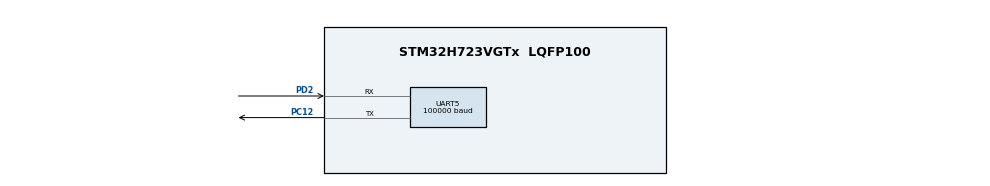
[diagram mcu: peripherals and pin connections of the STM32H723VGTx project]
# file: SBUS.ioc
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CORTEX_M7.default_mode_Activation=0
Dma.Request0=UART5_RX
Dma.UART5_RX.0.Direction=DMA_PERIPH_TO_MEMORY
Dma.UART5_RX.0.EventEnable=DISABLE
Dma.UART5_RX.0.FIFOMode=DMA_FIFOMODE_DISABLE
Dma.UART5_RX.0.Instance=DMA1_Stream0
Dma.UART5_RX.0.MemDataAlignment=DMA_MDATAALIGN_BYTE
Dma.UART5_RX.0.MemInc=DMA_MINC_ENABLE
Dma.UART5_RX.0.Mode=DMA_CIRCULAR
Dma.UART5_RX.0.PeriphDataAlignment=DMA_PDATAALIGN_BYTE
Dma.UART5_RX.0.PeriphInc=DMA_PINC_DISABLE
Dma.UART5_RX.0.Polarity=HAL_DMAMUX_REQ_GEN_RISING
Dma.UART5_RX.0.Priority=DMA_PRIORITY_VERY_HIGH
Dma.UART5_RX.0.RequestNumber=1
Dma.UART5_RX.0.SignalID=NONE
Dma.UART5_RX.0.SyncEnable=DISABLE
Dma.UART5_RX.0.SyncPolarity=HAL_DMAMUX_SYNC_NO_EVENT
Dma.UART5_RX.0.SyncRequestNumber=1
Dma.UART5_RX.0.SyncSignalID=NONE
Mcu.Family=STM32H7
Mcu.Name=STM32H723VGTx
Mcu.Package=LQFP100
NVIC.DMA1_Stream0_IRQn=true\:0\:0\:false\:false\:true\:false\:true\:true
NVIC.PriorityGroup=NVIC_PRIORITYGROUP_4
NVIC.UART5_IRQn=true\:0\:0\:false\:false\:true\:true\:true\:true
PA13(JTMS/SWDIO).Mode=Serial_Wire
PA13(JTMS/SWDIO).Signal=DEBUG_JTMS-SWDIO
PA14(JTCK/SWCLK).Mode=Serial_Wire
PA14(JTCK/SWCLK).Signal=DEBUG_JTCK-SWCLK
PC12.GPIO_Speed=GPIO_SPEED_FREQ_VERY_HIGH
PC12.Mode=Asynchronous
PC12.Signal=UART5_TX
PD2.GPIO_Speed=GPIO_SPEED_FREQ_VERY_HIGH
PD2.Mode=Asynchronous
PD2.Signal=UART5_RX
PH0-OSC_IN.Mode=HSE-External-Oscillator
PH0-OSC_IN.Signal=RCC_OSC_IN
PH1-OSC_OUT.Mode=HSE-External-Oscillator
PH1-OSC_OUT.Signal=RCC_OSC_OUT
ProjectManager.HeapSize=0x200
ProjectManager.StackSize=0x400
ProjectManager.TargetToolchain=MDK-ARM V5.32
RCC.ADCFreq_Value=48375000
RCC.APB1Freq_Value=120000000
RCC.APB2Freq_Value=120000000
RCC.APB3Freq_Value=120000000
RCC.APB4Freq_Value=120000000
RCC.CortexFreq_Value=480000000
RCC.D1PPRE=RCC_APB3_DIV2
RCC.D2PPRE1=RCC_APB1_DIV2
RCC.D2PPRE2=RCC_APB2_DIV2
RCC.D3PPRE=RCC_APB4_DIV2
RCC.DIVM1=2
RCC.DIVN1=40
RCC.DIVP1=1
RCC.HCLKFreq_Value=240000000
RCC.HPRE=RCC_HCLK_DIV2
RCC.HSE_VALUE=24000000
RCC.PLLFRACN=0
RCC.PLLSourceVirtual=RCC_PLLSOURCE_HSE
RCC.SYSCLKFreq_VALUE=480000000
RCC.SYSCLKSource=RCC_SYSCLKSOURCE_PLLCLK
RCC.USBFreq_Value=240000000
UART5.BaudRate=100000
UART5.Parity=PARITY_EVEN
UART5.StopBits=UART_STOPBITS_2
UART5.WordLength=WORDLENGTH_9B
VP_MEMORYMAP_VS_MEMORYMAP.Mode=CurAppReg
board=custom

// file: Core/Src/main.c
/* USER CODE BEGIN Header */
/**
  ******************************************************************************
  * @file           : main.c
  * @brief          : Main program body
  ******************************************************************************
  * @attention
  *
  * Copyright (c) 2025 STMicroelectronics.
  * All rights reserved.
  *
  * This software is licensed under terms that can be found in the LICENSE file
  * in the root directory of this software component.
  * If no LICENSE file comes with this software, it is provided AS-IS.
  *
  ******************************************************************************
  */
/* USER CODE END Header */
#include "main.h"
#include "dma.h"
#include "memorymap.h"
#include "usart.h"
#include "gpio.h"

/* USER CODE BEGIN Includes */
#include "bsp_usart.h"
/* USER CODE END Includes */

void SystemClock_Config(void);

int main(void)
{

  /* MCU Configuration--------------------------------------------------------*/

  /* Reset of all peripherals, Initializes the Flash interface and the Systick. */
  HAL_Init();

  /* Configure the system clock */
  SystemClock_Config();

  /* Initialize all configured peripherals */
  MX_GPIO_Init();
  MX_DMA_Init();
  MX_UART5_Init();
  /* USER CODE BEGIN 2 */

  USART_RxDMA_MultiBuffer_Init(&huart5, (uint32_t *) SBUS_MultiRx_Buf[0], (uint32_t *) SBUS_MultiRx_Buf[1], SBUS_RX_BUF_NUM);

  /* USER CODE END 2 */

  /* Infinite loop */
  while (1)
  {

  }
}

void SystemClock_Config(void)
{
  RCC_OscInitTypeDef RCC_OscInitStruct = {0};
  RCC_ClkInitTypeDef RCC_ClkInitStruct = {0};

  /** Supply configuration update enable
  */
  HAL_PWREx_ConfigSupply(PWR_LDO_SUPPLY);

  /** Configure the main internal regulator output voltage
  */
  __HAL_PWR_VOLTAGESCALING_CONFIG(PWR_REGULATOR_VOLTAGE_SCALE0);

  while(!__HAL_PWR_GET_FLAG(PWR_FLAG_VOSRDY)) {}

  /** Initializes the RCC Oscillators according to the specified parameters
  * in the RCC_OscInitTypeDef structure.
  */
  RCC_OscInitStruct.OscillatorType = RCC_OSCILLATORTYPE_HSE;
  RCC_OscInitStruct.HSEState = RCC_HSE_ON;
  RCC_OscInitStruct.PLL.PLLState = RCC_PLL_ON;
  RCC_OscInitStruct.PLL.PLLSource = RCC_PLLSOURCE_HSE;
  RCC_OscInitStruct.PLL.PLLM = 2;
  RCC_OscInitStruct.PLL.PLLN = 40;
  RCC_OscInitStruct.PLL.PLLP = 1;
  RCC_OscInitStruct.PLL.PLLQ = 2;
  RCC_OscInitStruct.PLL.PLLR = 2;
  RCC_OscInitStruct.PLL.PLLRGE = RCC_PLL1VCIRANGE_3;
  RCC_OscInitStruct.PLL.PLLVCOSEL = RCC_PLL1VCOWIDE;
  RCC_OscInitStruct.PLL.PLLFRACN = 0;
  if (HAL_RCC_OscConfig(&RCC_OscInitStruct) != HAL_OK)
  {
    Error_Handler();
  }

  /** Initializes the CPU, AHB and APB buses clocks
  */
  RCC_ClkInitStruct.ClockType = RCC_CLOCKTYPE_HCLK|RCC_CLOCKTYPE_SYSCLK
                              |RCC_CLOCKTYPE_PCLK1|RCC_CLOCKTYPE_PCLK2
                              |RCC_CLOCKTYPE_D3PCLK1|RCC_CLOCKTYPE_D1PCLK1;
  RCC_ClkInitStruct.SYSCLKSource = RCC_SYSCLKSOURCE_PLLCLK;
  RCC_ClkInitStruct.SYSCLKDivider = RCC_SYSCLK_DIV1;
  RCC_ClkInitStruct.AHBCLKDivider = RCC_HCLK_DIV2;
  RCC_ClkInitStruct.APB3CLKDivider = RCC_APB3_DIV2;
  RCC_ClkInitStruct.APB1CLKDivider = RCC_APB1_DIV2;
  RCC_ClkInitStruct.APB2CLKDivider = RCC_APB2_DIV2;
  RCC_ClkInitStruct.APB4CLKDivider = RCC_APB4_DIV2;

  if (HAL_RCC_ClockConfig(&RCC_ClkInitStruct, FLASH_LATENCY_3) != HAL_OK)
  {
    Error_Handler();
  }
}

void Error_Handler(void)
{
  __disable_irq();
  while (1)
  {
  }
}
